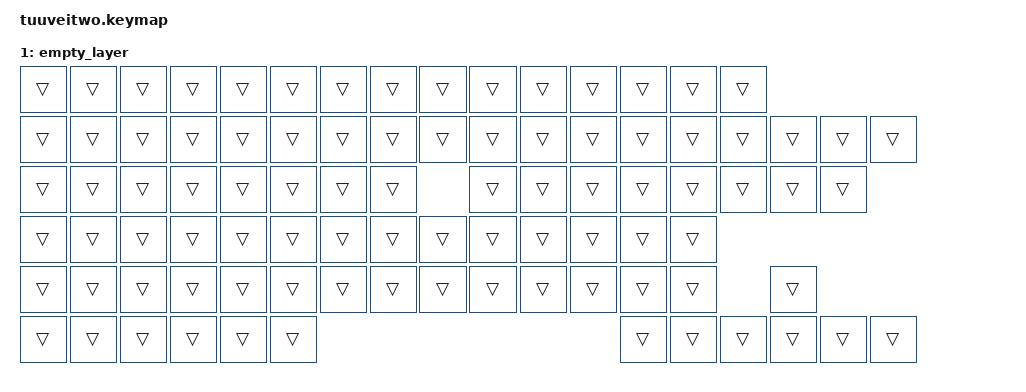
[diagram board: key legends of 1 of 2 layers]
/*
 * Copyright (c) 2022 The ZMK Contributors
 *
 * SPDX-License-Identifier: MIT
 */

#include <behaviors.dtsi>
#include <dt-bindings/zmk/keys.h>
#include <dt-bindings/zmk/bt.h>

#include <behaviors/num_word.dtsi> // Requires zmk-auto-layer module.
#include <behaviors/unicode.dtsi> // Requires zmk-unicode module.
#include <zmk-helpers/helper.h> // Requires zmk-helpers module.
#include <dt-bindings/zmk/mouse.h>

#include "zmk-helpers/helper.h"

#define WIN 0
#define MAC 1

#define AS(keycode) &as LS(keycode) keycode

#define KEYS_L 33 34 35 36 37 38 49 50 51 52 53 54 63 64 65 66 67 68
#define KEYS_R 39 40 41 42 43 44 45 55 56 57 58 59 60 61 69 70 71 72 73 74
#define KEYS_T 80 82

#define COMBO_TERM_FAST 35
#define COMBO_TERM_SLOW 50
#define COMBO_GLOBAL_QUICKTAP 100

#define MACRO(_name_, _bindings_)          \
_name_: _name_##_macro {                   \
    compatible     = "zmk,behavior-macro"; \
    #binding-cells = <0>;                  \
    tap-ms         = <1>;                  \
    wait-ms        = <1>;                  \
    bindings       = <_bindings_>;         \
};

/ {
    macros {
        MACRO(backtick,  &kp LS(EQUAL) &kp SPACE)
        MACRO(caret,  &kp LS(RIGHT_BRACKET) &kp SPACE) 
        MACRO(tilde, &kp RA(RIGHT_BRACKET) &kp SPACE)
    };
};

#define MODMORPH(_name_, _bindings_, _bindings_shift_)               \
_name_: _name_##_modmorph {                                          \
    compatible = "zmk,behavior-mod-morph";                           \
    #binding-cells = <0>;                                            \
    bindings = <_bindings_>, <_bindings_shift_>;                     \
    mods = <(MOD_LSFT | MOD_RSFT)>;                                  \
};

#define COMBO(_name_, _bindings_, _key_positions_, _layers_)    \
combo_##_name_ {                                                \
    timeout-ms            = <COMBO_TERM_FAST>;                  \
    require-prior-idle-ms = <COMBO_GLOBAL_QUICKTAP>;            \
    bindings              = <_bindings_>;                       \
    key-positions         = <_key_positions_>;                  \
    layers                = <_layers_>;                         \
};

/ { 

    combos {
        compatible = "zmk,combos";

//        0             1             2             3             4                  5             6             7             8             9
//
//
//
// ╭─────────────┬─────────────┬─────────────┬─────────────┬─────────────╮    ╭─────────────┬─────────────┬─────────────┬─────────────┬─────────────╮                                                                                                                                 ──────┬─────────────┬─────────────┬───────────┬─────────────╮
//            ┌─────┐       ┌─────┐       ┌─────┐       ┌─────┐                          ┌─────┐       ┌─────┐       ┌─────┐       ┌─────┐
//        F   │hakea│   P   │ Tab │   L   │ { } │   H   │  €  │   B                  W   │     │   G   │ "   │   O   │  ?  │  . :  │     │   Q
//            └──┬──┘    ┌──└──┬──┘──┐ ┌──└──┬──┘──┐ ┌──└──┬──┘──┐                    ┌──└──┬──┘──┐ ┌──└──┬──┘──┐ ┌──└──┬──┘──┐    └──┬──┘
// ├─────────────┼───────│QckSw│Swtch│─│     │ [ ] │─│     │  @  │───────┤    ├───────│     │     │─│ ' ´ │     │─│     │  !  │───────┼─────────────┤                                                                                                                                 ──────┼─────────────┼─────────────┼─────────────┼─────────────┤
//            ┌─────┐    └──┌─────┐──┘ └──┌─────┐──┘ └──┌─────┐──┘                    └──┌─────┐──┘ └──┌─────┐──┘ └──┌─────┐──┘    ┌─────┐
//      7 S   │stnk1│ 5 T   │ Esc │ 3 N   │ ( ) │ 1 K   │     │   V                0 C   │     │ 2 U   │Rtrn │ 4 A   │Bs Dl│ 6 E   │     │ 8 I
//      Ctrl  └──┬──┘ Alt┌──└──┬──┘──Gui──└──┬──┘──Num──└──┬──┘──┐                    ┌──└──┬──┘──Num──└──┬──┘──Gui──└──┬──┘──┐Alt └──┬──┘ Ctrl
// ├─────────────┼───────│Copy │Paste│─│     │ < > │─│     │  $  │───────┤    ├───────│     │     │─│ = % │  :  │─│  |  │ / \ │───────┼─────────────┤                                                                                                                                 ──────┼─────────────┼─────────────┼─────────────┼─────────────┤
//            ┌─────┐    └──┌─────┐──┘ └──┌─────┐──┘ └──┌─────┐──┘                    └──┌─────┐──┘ └──┌─────┐──┘ └──┌─────┐──┘    ┌─────┐
//        J   │     │   D   │ ~ ^ │   R   │ & # │ 9 M   │     │   X                8 Z   │     │   Y   │ + * │   Ä   │ - _ │   Ö   │     │  , ;
//            └──┬──┘       └──┬──┘       └──┬──┘       └──┬──┘                          └──┬──┘       └──┬──┘       └──┬──┘       └──┬──┘
// ╰─────────────┼─────────────┼─────────────┼─────────────┼─────────────┤    ├─────────────┼─────────────┼─────────────┼─────────────┼─────────────╯                                                                                                                                 ──────┼─────────────┼─────────────┼─────────────┼─────────────╯
//
//                                               SmrtShft     Repeater           L2 + Space    L3 + Rtrn
//
//                                           ╰─────────────┼─────────────┤    ├─────────────┼─────────────╯
//
//
//
        // 1 and 1+2 row combos left hand
//        COMBO(tog_hakea,        &tog HAKEA,           0 1, WIN MAC NUM MOUSE NAV HAKEA REPEAT)
//        COMBO(tog_stnk1,        &tog REPEAT,           10 11, WIN MAC NUM MOUSE NAV HAKEA REPEAT)
//        COMBO(TAB,              &kp TAB,              1 2, WIN MAC)
//        COMBO(br_curly_mac,     &mod_br_curly_mac,    2 3, MAC)
//        COMBO(br_curly_win,     &mod_br_curly_win,    2 3, WIN)
//        COMBO(euro_mac,         &kp LS(NUMBER_4),     3 4, MAC)
//        COMBO(euro_win,         &kp RA(E),            3 4, WIN)
//        COMBO(br_square,        &mod_br_square,       2 13, WIN MAC)
//        COMBO(at,               &kp RA(NUMBER_2),     3 14, WIN MAC)
//        COMBO(switcher_mac,     &switcher_mac,        1 12, MAC NUM)
//        COMBO(quick_sw_mac,     &quick_sw_mac,        11 2, MAC NUM)
//        COMBO(switcher_win,     &switcher_win,        1 12, WIN NUM)
//        COMBO(quick_sw_win,     &quick_sw_win,        11 2, WIN NUM)
//        
//        // 1 and 1+2 row combos right hand
//        COMBO(doublequote,      &kp LS(NUMBER_2),     6 7, WIN MAC)
//        COMBO(question,         &kp LS(MINUS),        7 8, WIN MAC)
//        COMBO(exclamation,      &kp LS(NUMBER_1),     7 18, WIN MAC)
//        COMBO(squot_btick,      &mod_squot_btick,     16 7, WIN MAC)
//        COMBO(copy_mac,         &kp LG(C),            15 6, MAC NUM)
//        COMBO(copy_win,         &kp LC(C),            16 7, WIN NUM)
//
//        // 2 and 2+3 row combos left hand
//        COMBO(esc,              &kp ESC,              11 12, WIN MAC)
//        COMBO(br_round,         &mod_br_round,        12 13, WIN MAC)
//        COMBO(br_angled_mac,    &mod_br_angled_mac,   12 23, MAC)
//        COMBO(br_angled_win,    &mod_br_angled_win,   12 23, WIN)
//        COMBO(dollar,           &kp RA(NUMBER_4),     13 24, WIN MAC)
//
        // 2 and 2+3 row combos right hand
//        COMBO(enter,            &kp RET,              56 57, WIN MAC)
//        COMBO(backspace_delete, &mod_bspc_del,        57 58, WIN MAC)
//        COMBO(equals_percent,   &mod_equals_percent,  26 17, WIN MAC)
//        COMBO(colon,            &kp LS(DOT),          27 16, WIN MAC)
//        COMBO(mod_slashes_win,  &mod_slashes_win,     17 28, WIN)
//        COMBO(mod_slashes_mac,  &mod_slashes_mac,     17 28, MAC)
//        COMBO(pipe_mac,         &kp RA(NUMBER_7),     27 18, MAC)
//        COMBO(pipe_win,         &kp RA(NON_US_BSLH),  27 18, WIN)
//        COMBO(paste_mac,        &kp LG(V),            25 16, MAC)
//        COMBO(paste_win,        &kp LC(V),            26 17, WIN)
//
//        // 3 row combos left hand
//        COMBO(amp_hash,         &mod_amp_hash,        22 23, WIN MAC)
//        COMBO(tilde_caret,      &mod_tilde_caret,     21 22, WIN MAC)
//
//        // 3 row combos right hand
//        COMBO(plus_asterisk,    &mod_plus_asterisk,   26 27, WIN MAC)
//        COMBO(minus,            &kp SLASH,            27 28, WIN MAC)
//      
//        // mixed combos
//        COMBO(toggle_win_mac,   &tog MAC,             30 31 32 33, WIN MAC)
//        COMBO(toggle_mouse,     &tog MOUSE,           6 8, WIN MAC)
//        COMBO(toggle_num,       &tog NUM,             13 16, WIN MAC)
//        COMBO(toggle_unlock,    &studio_unlock,       4 5, WIN MAC)

    };

    behaviors {
       skq: sticky_key_quick_release {
        compatible = "zmk,behavior-sticky-key";
        #binding-cells = <1>;
        bindings = <&kp>;
        release-after-ms = <1000>;
        quick-release;
        ignore-modifiers;
      };
        lt_bspc_del: layer_tap_backspace_delete {
            compatible = "zmk,behavior-hold-tap";
            #binding-cells = <2>;
            tapping-term-ms = <200>;
            //flavor = "tap-preferred";
            bindings = <&mo>, <&mod_bspc_del>;
        };
        MODMORPH(mod_br_curly_mac, &kp RA(RS(NUMBER_8)), &kp RA(RS(NUMBER_9)))
        MODMORPH(mod_br_curly_win, &kp RA(NUMBER_7), &kp RA(NUMBER_0))
        MODMORPH(mod_br_round, &kp LS(NUMBER_8), &kp LS(NUMBER_9))
        MODMORPH(mod_br_square, &kp RA(NUMBER_8), &kp RA(NUMBER_9))
        MODMORPH(mod_br_angled_win, &kp NON_US_BSLH, &kp LS(NON_US_BSLH))
        MODMORPH(mod_br_angled_mac, &kp GRAVE, &kp LS(GRAVE))
        MODMORPH(mod_bspc_del, &kp BACKSPACE, &kp DELETE)
        MODMORPH(mod_amp_hash, &kp LS(NUMBER_6), &kp LS(NUMBER_3))
        MODMORPH(mod_squot_btick, &kp BACKSLASH, &backtick)
        MODMORPH(mod_equals_percent, &kp LS(NUMBER_0), &kp LS(NUMBER_5))
        MODMORPH(mod_tilde_caret, &tilde, &caret)
        MODMORPH(mod_slashes_mac, &kp LS(NUMBER_7), &kp RA(LS(NUMBER_7)))
        MODMORPH(mod_slashes_win, &kp LS(NUMBER_7), &kp RA(MINUS))
        MODMORPH(mod_plus_asterisk, &kp MINUS ,&kp LS(BACKSLASH))

  };
    keymap {
    compatible = "zmk,keymap";
            default_layer {

        bindings = <
       &kp ESC            &kp F1   &kp F2   &kp F3   &kp F4   &kp F5   &kp F6   &kp F7   &kp F8   &kp F9  &kp F10   &kp F11   &kp F12   &kp PG_UP &kp PG_DN
       &kp GRAVE &kp N1   &kp N2   &kp N3   &kp N4   &kp N5   &kp N6   &kp N7   &kp N8   &kp N9   &kp N0  &kp MINUS &kp EQUAL &kp BSPC  &kp ENTER &kp INS   &kp HOME
       &kp TAB   &kp Q    &kp W    &kp E    &kp R    &kp T    &kp Y    &kp Y    &kp U    &kp I    &kp O    &kp P    &kp LBRC  &kp RBKT            &kp DEL  &kp END
       &kp CAPS  &kp A    &kp S    &kp D    &kp F    &kp G    &kp H    &kp H    &kp J    &kp K    &kp L    &kp SEMI &kp SQT   &kp BSLH
       &kp LSHFT &kp NUBS &kp Z    &kp X    &kp C    &kp V    &kp B    &kp B    &kp N    &kp M   &kp COMMA &kp DOT  &kp SLASH &kp LSHFT           &kp UP
       &kp LCTRL &kp LGUI &kp LALT &kp SPACE &kp C_MUTE                &kp SPACE         &kp RALT &kp LGUI &kp LCTRL                    &kp LEFT  &kp DOWN &kp RIGHT
        >;

        sensor-bindings = <&inc_dec_kp C_VOL_UP C_VOL_DN &inc_dec_kp PG_UP PG_DN>;
    };
      
    empty_layer {
        bindings = <
            &trans &trans &trans &trans &trans &trans &trans &trans &trans &trans &trans &trans &trans &trans &trans
            &trans &trans &trans &trans &trans &trans &trans &trans &trans &trans &trans &trans &trans &trans &trans &trans &trans &trans
            &trans &trans &trans &trans &trans &trans &trans &trans &trans &trans &trans &trans &trans &trans         &trans &trans
            &trans &trans &trans &trans &trans &trans &trans &trans &trans &trans &trans &trans &trans &trans
            &trans &trans &trans &trans &trans &trans &trans &trans &trans &trans &trans &trans &trans &trans         &trans
            &trans &trans &trans &trans &trans                 &trans         &trans &trans &trans                   &trans &trans &trans
        >;

        sensor-bindings = <&inc_dec_kp C_VOL_UP C_VOL_DN &inc_dec_kp PG_UP PG_DN>;
    };
    };
};

/*
 *      &kp ESC,           &kp F1,   &kp F2,   &kp F3,   &kp F4,         &kp F5,   &kp F6,   &kp F7,   &kp F8,       &kp F9,   &kp F10,  &kp F11,  &kp F12,    &kp PG_UP, &kp PG_DN,
 *      &kp GRAVE,  &kp N1,    &kp N2,    &kp N3,    &kp N4,    &kp N5,    &kp N6,             &kp N7,    &kp N8,    &kp N9,    &kp N0,    &kp MINUS, &kp EQUAL,  &kp BSPC,            &kp INS,  &kp HOME,
 *      &kp TAB,      &kp Q,    &kp W,    &kp E,    &kp R,    &kp T,    &kp Y,         &kp Y,    &kp U,    &kp I,    &kp O,    &kp P,    &kp LBRC, &kp RBRC,   &kp ENT,      &kp DEL,  &kp END,
 *      &kp CAPS,       &kp A,    &kp S,    &kp D,    &kp F,    &kp G,    &kp H,           &kp H,    &kp J,    &kp K,    &kp L,    &kp SCLN, &kp QUOT, &kp ASTR,
 *      &kp LSFT,   &kp BSLS, &kp Z,    &kp X,    &kp C,    &kp V,    &kp B,          &kp B,     &kp N,    &kp M,    &kp COMM, &kp DOT,  &kp SLSH, &kp LSFT,                   &kp UP,
 *      &kp LCTL,   &kp LGUI,   &kp LALT,   &kp SPC,    &kp PRINT_SCREEN,           &kp SPC,                  &kp RALT,   &kp LGUI,    &kp LCTL,       &kp LEFT, &kp DOWN, &kp RGHT
*/
